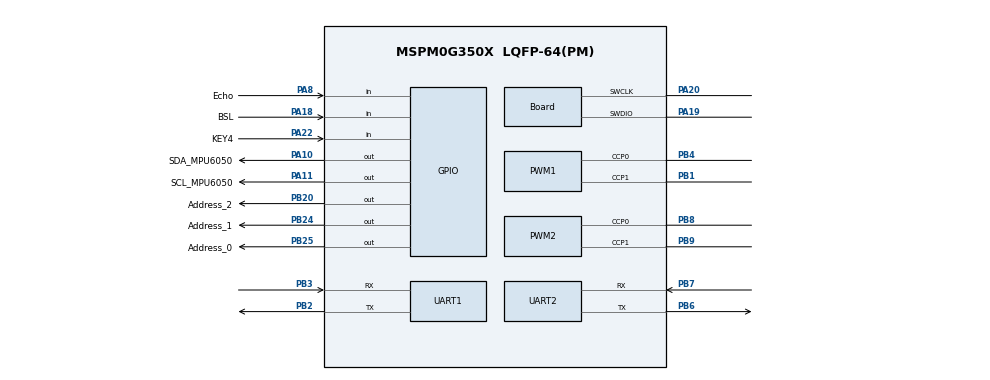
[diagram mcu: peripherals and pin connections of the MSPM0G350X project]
/**
 *
 * @cliArgs --device "MSPM0G350X" --part "Default" --package "LQFP-64(PM)" --product "mspm0_sdk@2.11.00.07"
 * @versions {"tool":"1.28.0+4712"}
 */

/**
 * Import the modules used in this configuration.
 */
const ADC12         = scripting.addModule("/ti/driverlib/ADC12", {}, false);
const ADC121        = ADC12.addInstance();
const GPIO          = scripting.addModule("/ti/driverlib/GPIO", {}, false);
const GPIO1         = GPIO.addInstance();
const GPIO2         = GPIO.addInstance();
const GPIO3         = GPIO.addInstance();
const GPIO4         = GPIO.addInstance();
const GPIO5         = GPIO.addInstance();
const GPIO6         = GPIO.addInstance();
const GPIO7         = GPIO.addInstance();
const GPIO8         = GPIO.addInstance();
const GPIO9         = GPIO.addInstance();
const PWM           = scripting.addModule("/ti/driverlib/PWM", {}, false);
const PWM1          = PWM.addInstance();
const PWM2          = PWM.addInstance();
const SYSCTL        = scripting.addModule("/ti/driverlib/SYSCTL");
const TIMER         = scripting.addModule("/ti/driverlib/TIMER", {}, false);
const TIMER1        = TIMER.addInstance();
const TIMER2        = TIMER.addInstance();
const TIMER3        = TIMER.addInstance();
const TIMER4        = TIMER.addInstance();
const UART          = scripting.addModule("/ti/driverlib/UART", {}, false);
const UART1         = UART.addInstance();
const UART2         = UART.addInstance();
const UART3         = UART.addInstance();
const ProjectConfig = scripting.addModule("/ti/project_config/ProjectConfig");

/**
 * Write custom configuration values to the imported modules.
 */
ADC121.$name                       = "ADC0";
ADC121.sampClkDiv                  = "DL_ADC12_CLOCK_DIVIDE_8";
ADC121.adcMem4chansel              = "DL_ADC12_INPUT_CHAN_4";
ADC121.startAdd                    = 11;
ADC121.adcMem11_name               = "ADC_Channel12";
ADC121.adcMem11chansel             = "DL_ADC12_INPUT_CHAN_12";
ADC121.endAdd                      = 11;
ADC121.repeatMode                  = true;
ADC121.sampClkSrc                  = "DL_ADC12_CLOCK_ULPCLK";
ADC121.enableFIFO                  = true;
ADC121.powerDownMode               = "DL_ADC12_POWER_DOWN_MODE_MANUAL";
ADC121.sampleTime0                 = "0ms";
ADC121.peripheral.$assign          = "ADC0";
ADC121.peripheral.adcPin12.$assign = "PA14";
ADC121.adcPin12Config.$name        = "ti_driverlib_gpio_GPIOPinGeneric8";

const Board                       = scripting.addModule("/ti/driverlib/Board", {}, false);
Board.peripheral.$assign          = "DEBUGSS";
Board.peripheral.swclkPin.$assign = "PA20";
Board.peripheral.swdioPin.$assign = "PA19";

GPIO1.$name                          = "LED";
GPIO1.associatedPins[0].assignedPort = "PORTB";
GPIO1.associatedPins[0].$name        = "LED_POWER";
GPIO1.associatedPins[0].assignedPin  = "27";
GPIO1.associatedPins[0].initialValue = "SET";

GPIO2.$name                               = "KEY";
GPIO2.port                                = "PORTA";
GPIO2.portSegment                         = "Upper";
GPIO2.associatedPins.create(5);
GPIO2.associatedPins[0].direction         = "INPUT";
GPIO2.associatedPins[0].$name             = "KEY1";
GPIO2.associatedPins[0].assignedPin       = "25";
GPIO2.associatedPins[1].direction         = "INPUT";
GPIO2.associatedPins[1].internalResistor  = "PULL_UP";
GPIO2.associatedPins[1].interruptPriority = "0";
GPIO2.associatedPins[1].$name             = "KEY2";
GPIO2.associatedPins[1].assignedPin       = "26";
GPIO2.associatedPins[2].$name             = "KEY3";
GPIO2.associatedPins[2].direction         = "INPUT";
GPIO2.associatedPins[2].assignedPin       = "27";
GPIO2.associatedPins[3].$name             = "KEY4";
GPIO2.associatedPins[3].direction         = "INPUT";
GPIO2.associatedPins[3].assignedPin       = "22";
GPIO2.associatedPins[3].pin.$assign       = "PA22";
GPIO2.associatedPins[4].$name             = "BSL";
GPIO2.associatedPins[4].direction         = "INPUT";
GPIO2.associatedPins[4].assignedPin       = "18";
GPIO2.associatedPins[4].pin.$assign       = "PA18";

GPIO3.port                               = "PORTA";
GPIO3.portSegment                        = "Upper";
GPIO3.$name                              = "IIC";
GPIO3.associatedPins.create(2);
GPIO3.associatedPins[0].assignedPin      = "31";
GPIO3.associatedPins[0].$name            = "SCL";
GPIO3.associatedPins[0].internalResistor = "PULL_UP";
GPIO3.associatedPins[1].assignedPin      = "28";
GPIO3.associatedPins[1].$name            = "SDA";
GPIO3.associatedPins[1].internalResistor = "PULL_UP";

GPIO4.$name                         = "buzzer";
GPIO4.port                          = "PORTB";
GPIO4.portSegment                   = "Upper";
GPIO4.associatedPins[0].$name       = "PIN_buzzer";
GPIO4.associatedPins[0].assignedPin = "17";

GPIO5.$name                         = "IIC_MPU6050";
GPIO5.port                          = "PORTA";
GPIO5.portSegment                   = "Lower";
GPIO5.associatedPins.create(2);
GPIO5.associatedPins[0].$name       = "SCL_MPU6050";
GPIO5.associatedPins[0].assignedPin = "11";
GPIO5.associatedPins[0].pin.$assign = "PA11";
GPIO5.associatedPins[1].$name       = "SDA_MPU6050";
GPIO5.associatedPins[1].assignedPin = "10";
GPIO5.associatedPins[1].pin.$assign = "PA10";

GPIO6.$name                          = "MOTOR";
GPIO6.associatedPins.create(4);
GPIO6.associatedPins[0].$name        = "AIN1";
GPIO6.associatedPins[0].assignedPort = "PORTA";
GPIO6.associatedPins[0].assignedPin  = "13";
GPIO6.associatedPins[1].$name        = "AIN2";
GPIO6.associatedPins[1].assignedPort = "PORTA";
GPIO6.associatedPins[1].assignedPin  = "12";
GPIO6.associatedPins[2].$name        = "BIN1";
GPIO6.associatedPins[2].assignedPort = "PORTB";
GPIO6.associatedPins[2].assignedPin  = "0";
GPIO6.associatedPins[3].$name        = "BIN2";
GPIO6.associatedPins[3].assignedPort = "PORTB";
GPIO6.associatedPins[3].assignedPin  = "16";

GPIO7.$name                               = "ENCODER";
GPIO7.port                                = "PORTA";
GPIO7.associatedPins.create(4);
GPIO7.associatedPins[0].$name             = "ENCODER1A";
GPIO7.associatedPins[0].direction         = "INPUT";
GPIO7.associatedPins[0].assignedPin       = "15";
GPIO7.associatedPins[0].interruptEn       = true;
GPIO7.associatedPins[0].polarity          = "RISE";
GPIO7.associatedPins[0].interruptPriority = "0";
GPIO7.associatedPins[1].$name             = "ENCODER1B";
GPIO7.associatedPins[1].direction         = "INPUT";
GPIO7.associatedPins[1].assignedPin       = "16";
GPIO7.associatedPins[1].interruptEn       = true;
GPIO7.associatedPins[1].polarity          = "RISE";
GPIO7.associatedPins[1].interruptPriority = "0";
GPIO7.associatedPins[2].$name             = "ENCODER2A";
GPIO7.associatedPins[2].direction         = "INPUT";
GPIO7.associatedPins[2].assignedPin       = "17";
GPIO7.associatedPins[2].interruptEn       = true;
GPIO7.associatedPins[2].polarity          = "RISE";
GPIO7.associatedPins[2].interruptPriority = "0";
GPIO7.associatedPins[3].$name             = "ENCODER2B";
GPIO7.associatedPins[3].direction         = "INPUT";
GPIO7.associatedPins[3].assignedPin       = "24";
GPIO7.associatedPins[3].interruptEn       = true;
GPIO7.associatedPins[3].polarity          = "RISE";
GPIO7.associatedPins[3].interruptPriority = "0";

GPIO8.$name                         = "Grayscale";
GPIO8.port                          = "PORTB";
GPIO8.portSegment                   = "Upper";
GPIO8.associatedPins.create(3);
GPIO8.associatedPins[0].$name       = "Address_0";
GPIO8.associatedPins[0].assignedPin = "25";
GPIO8.associatedPins[0].pin.$assign = "PB25";
GPIO8.associatedPins[1].$name       = "Address_1";
GPIO8.associatedPins[1].assignedPin = "24";
GPIO8.associatedPins[1].pin.$assign = "PB24";
GPIO8.associatedPins[2].$name       = "Address_2";
GPIO8.associatedPins[2].assignedPin = "20";
GPIO8.associatedPins[2].pin.$assign = "PB20";

GPIO9.$name                          = "SR04";
GPIO9.port                           = "PORTA";
GPIO9.portSegment                    = "Lower";
GPIO9.associatedPins.create(2);
GPIO9.associatedPins[0].$name        = "Trig";
GPIO9.associatedPins[0].initialValue = "SET";
GPIO9.associatedPins[0].assignedPin  = "9";
GPIO9.associatedPins[1].$name        = "Echo";
GPIO9.associatedPins[1].direction    = "INPUT";
GPIO9.associatedPins[1].assignedPin  = "8";
GPIO9.associatedPins[1].polarity     = "RISE_FALL";
GPIO9.associatedPins[1].pin.$assign  = "PA8";

PWM1.$name                      = "PWM_0";
PWM1.timerStartTimer            = true;
PWM1.peripheral.ccp0Pin.$assign = "PB4";
PWM1.peripheral.ccp1Pin.$assign = "PB1";
PWM1.PWM_CHANNEL_0.$name        = "ti_driverlib_pwm_PWMTimerCC0";
PWM1.PWM_CHANNEL_0.invert       = true;
PWM1.PWM_CHANNEL_1.$name        = "ti_driverlib_pwm_PWMTimerCC1";
PWM1.PWM_CHANNEL_1.invert       = true;
PWM1.ccp0PinConfig.$name        = "ti_driverlib_gpio_GPIOPinGeneric6";
PWM1.ccp1PinConfig.$name        = "ti_driverlib_gpio_GPIOPinGeneric7";

PWM2.$name                      = "PWM_1";
PWM2.clockDivider               = 8;
PWM2.timerCount                 = 320;
PWM2.clockPrescale              = 250;
PWM2.peripheral.$assign         = "TIMA0";
PWM2.peripheral.ccp0Pin.$assign = "PB8";
PWM2.peripheral.ccp1Pin.$assign = "PB9";
PWM2.PWM_CHANNEL_0.$name        = "ti_driverlib_pwm_PWMTimerCC2";
PWM2.PWM_CHANNEL_1.$name        = "ti_driverlib_pwm_PWMTimerCC3";
PWM2.ccp0PinConfig.$name        = "ti_driverlib_gpio_GPIOPinGeneric9";
PWM2.ccp1PinConfig.$name        = "ti_driverlib_gpio_GPIOPinGeneric10";

SYSCTL.clockTreeEn = true;

TIMER1.$name              = "TIMER_1";
TIMER1.timerClkPrescale   = 100;
TIMER1.interrupts         = ["ZERO"];
TIMER1.timerMode          = "PERIODIC";
TIMER1.timerPeriod        = "10ms";
TIMER1.peripheral.$assign = "TIMG0";

TIMER2.$name            = "TIMER_2";
TIMER2.timerClkPrescale = 100;
TIMER2.interrupts       = ["ZERO"];
TIMER2.timerMode        = "PERIODIC";
TIMER2.timerPeriod      = "18ms";

TIMER3.$name            = "TIMER_3";
TIMER3.interrupts       = ["ZERO"];
TIMER3.timerMode        = "PERIODIC";
TIMER3.timerClkPrescale = 100;
TIMER3.timerPeriod      = "10ms";

TIMER4.$name             = "TIMEG_0";
TIMER4.timerMode         = "PERIODIC";
TIMER4.timerClkDiv       = 8;
TIMER4.timerClkPrescale  = 2;
TIMER4.interrupts        = ["ZERO"];
TIMER4.timerPeriod       = "10ms";
TIMER4.interruptPriority = "1";

UART1.targetBaudRate                   = 115200;
UART1.rxFifoThreshold                  = "DL_UART_RX_FIFO_LEVEL_ONE_ENTRY";
UART1.enableDMARX                      = false;
UART1.enableDMATX                      = false;
UART1.$name                            = "UART_3_camera";
UART1.enabledInterrupts                = ["RX"];
UART1.uartClkDiv                       = "2";
UART1.interruptPriority                = "0";
UART1.peripheral.$assign               = "UART3";
UART1.peripheral.rxPin.$assign         = "PB3";
UART1.peripheral.txPin.$assign         = "PB2";
UART1.txPinConfig.direction            = scripting.forceWrite("OUTPUT");
UART1.txPinConfig.hideOutputInversion  = scripting.forceWrite(false);
UART1.txPinConfig.onlyInternalResistor = scripting.forceWrite(false);
UART1.txPinConfig.passedPeripheralType = scripting.forceWrite("Digital");
UART1.txPinConfig.$name                = "ti_driverlib_gpio_GPIOPinGeneric2";
UART1.rxPinConfig.hideOutputInversion  = scripting.forceWrite(false);
UART1.rxPinConfig.onlyInternalResistor = scripting.forceWrite(false);
UART1.rxPinConfig.passedPeripheralType = scripting.forceWrite("Digital");
UART1.rxPinConfig.$name                = "ti_driverlib_gpio_GPIOPinGeneric3";

UART2.enableDMARX                      = false;
UART2.enableDMATX                      = false;
UART2.$name                            = "UART_1_BT24";
UART2.targetBaudRate                   = 115200;
UART2.enableFIFO                       = true;
UART2.rxFifoThreshold                  = "DL_UART_RX_FIFO_LEVEL_ONE_ENTRY";
UART2.enableInternalLoopback           = true;
UART2.enabledInterrupts                = ["RX"];
UART2.peripheral.$assign               = "UART1";
UART2.peripheral.rxPin.$assign         = "PB7";
UART2.peripheral.txPin.$assign         = "PB6";
UART2.txPinConfig.direction            = scripting.forceWrite("OUTPUT");
UART2.txPinConfig.hideOutputInversion  = scripting.forceWrite(false);
UART2.txPinConfig.onlyInternalResistor = scripting.forceWrite(false);
UART2.txPinConfig.passedPeripheralType = scripting.forceWrite("Digital");
UART2.txPinConfig.$name                = "ti_driverlib_gpio_GPIOPinGeneric4";
UART2.rxPinConfig.hideOutputInversion  = scripting.forceWrite(false);
UART2.rxPinConfig.onlyInternalResistor = scripting.forceWrite(false);
UART2.rxPinConfig.passedPeripheralType = scripting.forceWrite("Digital");
UART2.rxPinConfig.$name                = "ti_driverlib_gpio_GPIOPinGeneric5";

UART3.$name                            = "UART_0";
UART3.targetBaudRate                   = 115200;
UART3.rxFifoThreshold                  = "DL_UART_RX_FIFO_LEVEL_ONE_ENTRY";
UART3.enableDMARX                      = false;
UART3.enableDMATX                      = false;
UART3.enabledInterrupts                = ["RX"];
UART3.txPinConfig.direction            = scripting.forceWrite("OUTPUT");
UART3.txPinConfig.hideOutputInversion  = scripting.forceWrite(false);
UART3.txPinConfig.onlyInternalResistor = scripting.forceWrite(false);
UART3.txPinConfig.passedPeripheralType = scripting.forceWrite("Digital");
UART3.txPinConfig.$name                = "ti_driverlib_gpio_GPIOPinGeneric0";
UART3.rxPinConfig.hideOutputInversion  = scripting.forceWrite(false);
UART3.rxPinConfig.onlyInternalResistor = scripting.forceWrite(false);
UART3.rxPinConfig.passedPeripheralType = scripting.forceWrite("Digital");
UART3.rxPinConfig.$name                = "ti_driverlib_gpio_GPIOPinGeneric1";

ProjectConfig.deviceSpin = "MSPM0G3507";

/**
 * Pinmux solution for unlocked pins/peripherals. This ensures that minor changes to the automatic solver in a future
 * version of the tool will not impact the pinmux you originally saw.  These lines can be completely deleted in order to
 * re-solve from scratch.
 */
GPIO1.associatedPins[0].pin.$suggestSolution = "PB27";
GPIO2.associatedPins[0].pin.$suggestSolution = "PA25";
GPIO2.associatedPins[1].pin.$suggestSolution = "PA26";
GPIO2.associatedPins[2].pin.$suggestSolution = "PA27";
GPIO3.associatedPins[0].pin.$suggestSolution = "PA31";
GPIO3.associatedPins[1].pin.$suggestSolution = "PA28";
GPIO4.associatedPins[0].pin.$suggestSolution = "PB17";
GPIO6.associatedPins[0].pin.$suggestSolution = "PA13";
GPIO6.associatedPins[1].pin.$suggestSolution = "PA12";
GPIO6.associatedPins[2].pin.$suggestSolution = "PB0";
GPIO6.associatedPins[3].pin.$suggestSolution = "PB16";
GPIO7.associatedPins[0].pin.$suggestSolution = "PA15";
GPIO7.associatedPins[1].pin.$suggestSolution = "PA16";
GPIO7.associatedPins[2].pin.$suggestSolution = "PA17";
GPIO7.associatedPins[3].pin.$suggestSolution = "PA24";
GPIO9.associatedPins[0].pin.$suggestSolution = "PA9";
PWM1.peripheral.$suggestSolution             = "TIMA1";
TIMER2.peripheral.$suggestSolution           = "TIMG8";
TIMER3.peripheral.$suggestSolution           = "TIMG7";
TIMER4.peripheral.$suggestSolution           = "TIMG6";
UART3.peripheral.$suggestSolution            = "UART0";
UART3.peripheral.rxPin.$suggestSolution      = "PA1";
UART3.peripheral.txPin.$suggestSolution      = "PA0";
